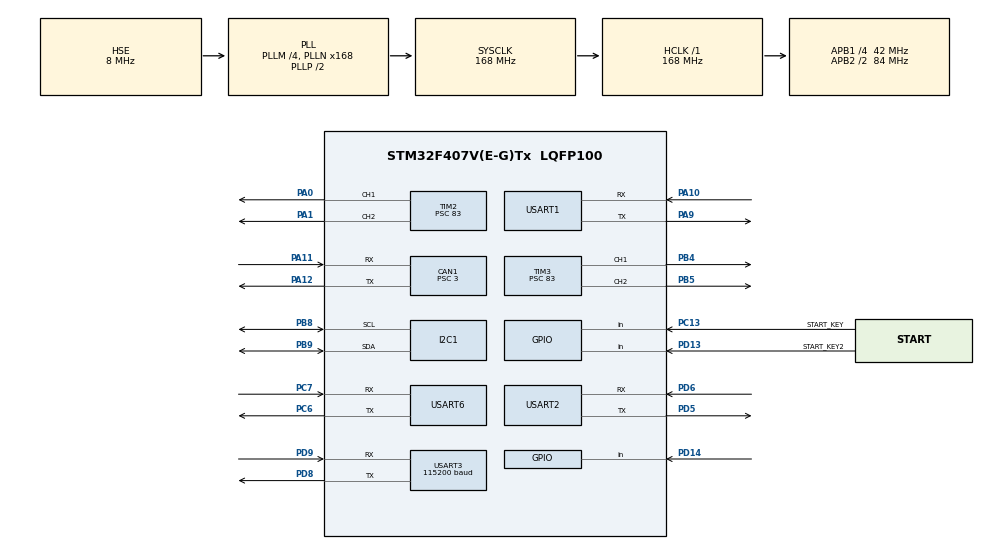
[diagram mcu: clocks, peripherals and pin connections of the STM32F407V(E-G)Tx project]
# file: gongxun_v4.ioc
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CAN1.BS1=CAN_BS1_12TQ
CAN1.CalculateBaudRate=1000000
CAN1.CalculateTimeBit=1000
CAN1.CalculateTimeQuantum=71.42857142857143
CAN1.Prescaler=3
Dma.Request0=USART3_RX
Dma.Request1=USART6_RX
Dma.Request2=USART1_RX
Dma.Request3=USART1_TX
Dma.USART1_RX.2.Direction=DMA_PERIPH_TO_MEMORY
Dma.USART1_RX.2.FIFOMode=DMA_FIFOMODE_DISABLE
Dma.USART1_RX.2.Instance=DMA2_Stream2
Dma.USART1_RX.2.MemDataAlignment=DMA_MDATAALIGN_BYTE
Dma.USART1_RX.2.MemInc=DMA_MINC_ENABLE
Dma.USART1_RX.2.Mode=DMA_NORMAL
Dma.USART1_RX.2.PeriphDataAlignment=DMA_PDATAALIGN_BYTE
Dma.USART1_RX.2.PeriphInc=DMA_PINC_DISABLE
Dma.USART1_RX.2.Priority=DMA_PRIORITY_LOW
Dma.USART1_TX.3.Direction=DMA_MEMORY_TO_PERIPH
Dma.USART1_TX.3.FIFOMode=DMA_FIFOMODE_DISABLE
Dma.USART1_TX.3.Instance=DMA2_Stream7
Dma.USART1_TX.3.MemDataAlignment=DMA_MDATAALIGN_BYTE
Dma.USART1_TX.3.MemInc=DMA_MINC_ENABLE
Dma.USART1_TX.3.Mode=DMA_NORMAL
Dma.USART1_TX.3.PeriphDataAlignment=DMA_PDATAALIGN_BYTE
Dma.USART1_TX.3.PeriphInc=DMA_PINC_DISABLE
Dma.USART1_TX.3.Priority=DMA_PRIORITY_LOW
Dma.USART3_RX.0.Direction=DMA_PERIPH_TO_MEMORY
Dma.USART3_RX.0.FIFOMode=DMA_FIFOMODE_DISABLE
Dma.USART3_RX.0.Instance=DMA1_Stream1
Dma.USART3_RX.0.MemDataAlignment=DMA_MDATAALIGN_BYTE
Dma.USART3_RX.0.MemInc=DMA_MINC_ENABLE
Dma.USART3_RX.0.Mode=DMA_NORMAL
Dma.USART3_RX.0.PeriphDataAlignment=DMA_PDATAALIGN_BYTE
Dma.USART3_RX.0.PeriphInc=DMA_PINC_DISABLE
Dma.USART3_RX.0.Priority=DMA_PRIORITY_LOW
Dma.USART6_RX.1.Direction=DMA_PERIPH_TO_MEMORY
Dma.USART6_RX.1.FIFOMode=DMA_FIFOMODE_DISABLE
Dma.USART6_RX.1.Instance=DMA2_Stream1
Dma.USART6_RX.1.MemDataAlignment=DMA_MDATAALIGN_BYTE
Dma.USART6_RX.1.MemInc=DMA_MINC_ENABLE
Dma.USART6_RX.1.Mode=DMA_NORMAL
Dma.USART6_RX.1.PeriphDataAlignment=DMA_PDATAALIGN_BYTE
Dma.USART6_RX.1.PeriphInc=DMA_PINC_DISABLE
Dma.USART6_RX.1.Priority=DMA_PRIORITY_LOW
FREERTOS.INCLUDE_vTaskDelayUntil=1
FREERTOS.Tasks01=defaultTask,24,1024,StartDefaultTask,As weak,NULL,Dynamic,NULL,NULL
FREERTOS.configTOTAL_HEAP_SIZE=24576
Mcu.Family=STM32F4
Mcu.Name=STM32F407V(E-G)Tx
Mcu.Package=LQFP100
NVIC.CAN1_RX0_IRQn=true\:5\:0\:false\:false\:true\:true\:true\:true\:true
NVIC.DMA1_Stream1_IRQn=true\:5\:0\:false\:false\:true\:true\:false\:true\:true
NVIC.DMA2_Stream1_IRQn=true\:6\:0\:true\:false\:true\:true\:false\:true\:true
NVIC.DMA2_Stream2_IRQn=true\:5\:0\:false\:false\:true\:true\:false\:true\:true
NVIC.DMA2_Stream7_IRQn=true\:5\:0\:false\:false\:true\:true\:false\:true\:true
NVIC.PriorityGroup=NVIC_PRIORITYGROUP_4
NVIC.TIM6_DAC_IRQn=true\:15\:0\:false\:false\:true\:false\:false\:true\:true
NVIC.TimeBase=TIM6_DAC_IRQn
NVIC.TimeBaseIP=TIM6
NVIC.USART1_IRQn=true\:7\:0\:true\:false\:true\:true\:true\:true\:true
NVIC.USART2_IRQn=true\:7\:0\:true\:false\:true\:true\:true\:true\:true
NVIC.USART3_IRQn=true\:5\:0\:true\:false\:true\:true\:true\:true\:true
NVIC.USART6_IRQn=true\:6\:0\:true\:false\:true\:true\:true\:true\:true
PA0-WKUP.Signal=S_TIM2_CH1_ETR
PA1.Signal=S_TIM2_CH2
PA10.Mode=Asynchronous
PA10.Signal=USART1_RX
PA11.Mode=CAN_Activate
PA11.Signal=CAN1_RX
PA12.Mode=CAN_Activate
PA12.Signal=CAN1_TX
PA13.Mode=Serial_Wire
PA13.Signal=SYS_JTMS-SWDIO
PA14.Mode=Serial_Wire
PA14.Signal=SYS_JTCK-SWCLK
PA9.Mode=Asynchronous
PA9.Signal=USART1_TX
PB4.GPIO_Speed=GPIO_SPEED_FREQ_VERY_HIGH
PB4.Signal=S_TIM3_CH1
PB5.GPIO_Speed=GPIO_SPEED_FREQ_VERY_HIGH
PB5.Signal=S_TIM3_CH2
PB8.Mode=I2C
PB8.Signal=I2C1_SCL
PB9.Mode=I2C
PB9.Signal=I2C1_SDA
PC13-ANTI_TAMP.GPIO_Label=START_KEY
PC13-ANTI_TAMP.GPIO_PuPd=GPIO_PULLUP
PC13-ANTI_TAMP.Signal=GPIO_Input
PC14-OSC32_IN.Mode=LSE-External-Oscillator
PC14-OSC32_IN.Signal=RCC_OSC32_IN
PC15-OSC32_OUT.Mode=LSE-External-Oscillator
PC15-OSC32_OUT.Signal=RCC_OSC32_OUT
PC6.Mode=Asynchronous
PC6.Signal=USART6_TX
PC7.Mode=Asynchronous
PC7.Signal=USART6_RX
PD13.GPIO_Label=START_KEY2
PD13.GPIO_PuPd=GPIO_PULLUP
PD13.Signal=GPIO_Input
PD14.GPIO_PuPd=GPIO_PULLUP
PD14.Signal=GPIO_Input
PD5.Mode=Asynchronous
PD5.Signal=USART2_TX
PD6.Mode=Asynchronous
PD6.Signal=USART2_RX
PD8.Mode=Asynchronous
PD8.Signal=USART3_TX
PD9.Mode=Asynchronous
PD9.Signal=USART3_RX
PH0-OSC_IN.Mode=HSE-External-Oscillator
PH0-OSC_IN.Signal=RCC_OSC_IN
PH1-OSC_OUT.Mode=HSE-External-Oscillator
PH1-OSC_OUT.Signal=RCC_OSC_OUT
ProjectManager.HeapSize=0x200
ProjectManager.StackSize=0x400
ProjectManager.TargetToolchain=CMake
RCC.48MHZClocksFreq_Value=84000000
RCC.AHBFreq_Value=168000000
RCC.APB1CLKDivider=RCC_HCLK_DIV4
RCC.APB1Freq_Value=42000000
RCC.APB1TimFreq_Value=84000000
RCC.APB2CLKDivider=RCC_HCLK_DIV2
RCC.APB2Freq_Value=84000000
RCC.APB2TimFreq_Value=168000000
RCC.CortexFreq_Value=168000000
RCC.HCLKFreq_Value=168000000
RCC.HSE_VALUE=8000000
RCC.HSI_VALUE=16000000
RCC.PLLM=4
RCC.PLLN=168
RCC.PLLSourceVirtual=RCC_PLLSOURCE_HSE
RCC.SYSCLKFreq_VALUE=168000000
RCC.SYSCLKSource=RCC_SYSCLKSOURCE_PLLCLK
RCC.VCOOutputFreq_Value=336000000
SH.S_TIM2_CH1_ETR.0=TIM2_CH1,PWM Generation1 CH1
SH.S_TIM2_CH2.0=TIM2_CH2,PWM Generation2 CH2
SH.S_TIM3_CH1.0=TIM3_CH1,PWM Generation1 CH1
SH.S_TIM3_CH2.0=TIM3_CH2,PWM Generation2 CH2
TIM2.Channel-PWM\ Generation1\ CH1=TIM_CHANNEL_1
TIM2.Channel-PWM\ Generation2\ CH2=TIM_CHANNEL_2
TIM2.Period=1999
TIM2.Prescaler=83
TIM3.Channel-PWM\ Generation1\ CH1=TIM_CHANNEL_1
TIM3.Channel-PWM\ Generation2\ CH2=TIM_CHANNEL_2
TIM3.Period=19999
TIM3.Prescaler=83
USART1.VirtualMode=VM_ASYNC
USART2.VirtualMode=VM_ASYNC
USART3.BaudRate=115200
USART3.VirtualMode=VM_ASYNC
USART6.VirtualMode=VM_ASYNC
VP_FREERTOS_VS_CMSIS_V2.Mode=CMSIS_V2
VP_SYS_VS_tim6.Mode=TIM6
board=custom

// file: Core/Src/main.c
/* USER CODE BEGIN Header */
/**
  ******************************************************************************
  * @file           : main.c
  * @brief          : Main program body
  ******************************************************************************
  * @attention
  *
  * Copyright (c) 2026 STMicroelectronics.
  * All rights reserved.
  *
  * This software is licensed under terms that can be found in the LICENSE file
  * in the root directory of this software component.
  * If no LICENSE file comes with this software, it is provided AS-IS.
  *
  ******************************************************************************
  */
/* USER CODE END Header */
#include "main.h"
#include "cmsis_os.h"
#include "can.h"
#include "dma.h"
#include "i2c.h"
#include "tim.h"
#include "usart.h"
#include "gpio.h"

void SystemClock_Config(void);
void MX_FREERTOS_Init(void);

int main(void)
{

  /* MCU Configuration--------------------------------------------------------*/

  /* Reset of all peripherals, Initializes the Flash interface and the Systick. */
  HAL_Init();

  /* Configure the system clock */
  SystemClock_Config();

  /* Initialize all configured peripherals */
  MX_GPIO_Init();
  MX_DMA_Init();
  MX_TIM3_Init();
  MX_USART1_UART_Init();
  MX_USART2_UART_Init();
  MX_USART3_UART_Init();
  MX_USART6_UART_Init();
  MX_CAN1_Init();
  MX_TIM2_Init();
  MX_I2C1_Init();
  /* USER CODE BEGIN 2 */
  /* ── 这里该放什么 ────────────────────────────────────────────────────
   * 只放"必须在调度器启动前、必须在所有 MX_xxx_Init() 之后"的初始化。
   *
   * 现在这里是空的，是有意的：
   *   串口接收的启动（Uart1_Init）放在任务的 LinkTest_Init() 里，
   *   因为它依赖 FreeRTOS 和环形缓冲，放在任务里更清晰。
   *
   * 以后底盘要初始化时，顺序记住这条：
   *   先让电机停住 → 再让陀螺仪静止校准 → 最后才允许动机构。
   *   （IMU 静校要求车体绝对不动，驱动器还在转的话零偏就是错的）
   *
   * ⚠️ 原来这里有一大段旧方案（uart_init_User / Emm_V5_Stop_Now /
   *    IMU_Start / action_Init）的说明，那些函数现在已经不存在了，
   *    注释已删除，避免误导。
   * ------------------------------------------------------------------------- */
  /* USER CODE END 2 */

  /* Init scheduler */
  osKernelInitialize();  /* Call init function for freertos objects (in cmsis_os2.c) */
  MX_FREERTOS_Init();

  /* Start scheduler */
  osKernelStart();

  /* We should never get here as control is now taken by the scheduler */

  /* Infinite loop */
  while (1)
  {

  }
}

void SystemClock_Config(void)
{
  RCC_OscInitTypeDef RCC_OscInitStruct = {0};
  RCC_ClkInitTypeDef RCC_ClkInitStruct = {0};

  /** Configure the main internal regulator output voltage
  */
  __HAL_RCC_PWR_CLK_ENABLE();
  __HAL_PWR_VOLTAGESCALING_CONFIG(PWR_REGULATOR_VOLTAGE_SCALE1);

  /** Initializes the RCC Oscillators according to the specified parameters
  * in the RCC_OscInitTypeDef structure.
  */
  RCC_OscInitStruct.OscillatorType = RCC_OSCILLATORTYPE_HSE;
  RCC_OscInitStruct.HSEState = RCC_HSE_ON;
  RCC_OscInitStruct.PLL.PLLState = RCC_PLL_ON;
  RCC_OscInitStruct.PLL.PLLSource = RCC_PLLSOURCE_HSE;
  RCC_OscInitStruct.PLL.PLLM = 4;
  RCC_OscInitStruct.PLL.PLLN = 168;
  RCC_OscInitStruct.PLL.PLLP = RCC_PLLP_DIV2;
  RCC_OscInitStruct.PLL.PLLQ = 4;
  if (HAL_RCC_OscConfig(&RCC_OscInitStruct) != HAL_OK)
  {
    Error_Handler();
  }

  /** Initializes the CPU, AHB and APB buses clocks
  */
  RCC_ClkInitStruct.ClockType = RCC_CLOCKTYPE_HCLK|RCC_CLOCKTYPE_SYSCLK
                              |RCC_CLOCKTYPE_PCLK1|RCC_CLOCKTYPE_PCLK2;
  RCC_ClkInitStruct.SYSCLKSource = RCC_SYSCLKSOURCE_PLLCLK;
  RCC_ClkInitStruct.AHBCLKDivider = RCC_SYSCLK_DIV1;
  RCC_ClkInitStruct.APB1CLKDivider = RCC_HCLK_DIV4;
  RCC_ClkInitStruct.APB2CLKDivider = RCC_HCLK_DIV2;

  if (HAL_RCC_ClockConfig(&RCC_ClkInitStruct, FLASH_LATENCY_5) != HAL_OK)
  {
    Error_Handler();
  }
}

void HAL_TIM_PeriodElapsedCallback(TIM_HandleTypeDef *htim)
{
  if (htim->Instance == TIM6)
  {
    HAL_IncTick();
  }
}

void Error_Handler(void)
{
  __disable_irq();
  while (1)
  {
  }
}

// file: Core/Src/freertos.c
/* USER CODE BEGIN Header */
/**
  ******************************************************************************
  * @file    freertos.c
  * @brief   FreeRTOS 任务创建与启动
  * @attention
  */
/* USER CODE END Header */

#include "FreeRTOS.h"
#include "task.h"
#include "main.h"
#include "cmsis_os.h"

/* USER CODE BEGIN Includes */
#include "link_test.h"      /* 第 6 步：把串口链路挂进任务 */
/* USER CODE END Includes */

/* USER CODE BEGIN Variables */
osThreadId defaultTaskHandle;
/* USER CODE END Variables */
/* Definitions for defaultTask */
osThreadId_t defaultTaskHandle;
const osThreadAttr_t defaultTask_attributes = {
  .name = "defaultTask",
  .stack_size = 1024 * 4,
  .priority = (osPriority_t) osPriorityNormal,
};

void StartDefaultTask(void *argument);

void MX_FREERTOS_Init(void); /* (MISRA C 2004 rule 8.1) */

void MX_FREERTOS_Init(void) {

  /* USER CODE BEGIN RTOS_MUTEX */
  /* 互斥量：以后两个任务同时访问同一份数据（比如航点队列）时在这里建 */
  /* USER CODE END RTOS_MUTEX */

  /* USER CODE BEGIN RTOS_SEMAPHORES */
  /* 信号量：以后"中断通知任务"时用（比轮询省 CPU） */
  /* USER CODE END RTOS_SEMAPHORES */

  /* USER CODE BEGIN RTOS_TIMERS */
  /* 软件定时器 */
  /* USER CODE END RTOS_TIMERS */

  /* USER CODE BEGIN RTOS_QUEUES */
  /* 消息队列：以后 CAN 收包、串口帧跨任务传递时用 */
  /* USER CODE END RTOS_QUEUES */

  /* Create the thread(s) */
  /* creation of defaultTask */
  defaultTaskHandle = osThreadNew(StartDefaultTask, NULL, &defaultTask_attributes);

  /* USER CODE BEGIN RTOS_THREADS */
  /* 以后在这里加第二个任务，例如 20ms 底盘任务：
   *   osThreadDef(chassisTask, StartChassisTask, osPriorityHigh, 0, 1024);
   *   chassisTaskHandle = osThreadCreate(osThread(chassisTask), NULL);
   */
  /* USER CODE END RTOS_THREADS */

}

/* USER CODE BEGIN Header_StartDefaultTask */
/**
  * @brief  默认任务：现在跑 USART1 通信链路
  * @param  argument: 未使用
  * @retval None
  */
/* USER CODE END Header_StartDefaultTask */
__weak void StartDefaultTask(void *argument)
{
  /* USER CODE BEGIN StartDefaultTask */
  (void)argument;       /* 参数没用，加 (void) 避免告警 */

  /* ── 初始化只做一次，所以放在 for 之前 ──
   * 注意顺序：LinkTest_Init() 内部会调 Uart1_Init()，
   * 而 Uart1_Init() 依赖 MX_USART1_UART_Init() 已经执行过——
   * 那是在 main() 里、调度器启动之前做的，所以这里一定满足。 */
  LinkTest_Init();

  /* ── 任务主循环 ──
   * ★FreeRTOS 的任务绝对不允许"跑完就返回"，必须是死循环。
   *   如果返回了，内核会触发 configASSERT 或者跑飞。
   *
   * osDelay(20) 让出 CPU 20ms。为什么不是 osDelay(1)：
   *   20ms 和我们的数据节奏匹配（心跳 500ms、以后位姿 20Hz），
   *   1ms 只是白白增加调度次数，没有收益。 */
  for(;;)
  {
    LinkTest_Step();    /* 收帧（拆包+校验+回ACK） + 每 500ms 发心跳 */
    osDelay(20);
  }
  /* USER CODE END StartDefaultTask */
}
